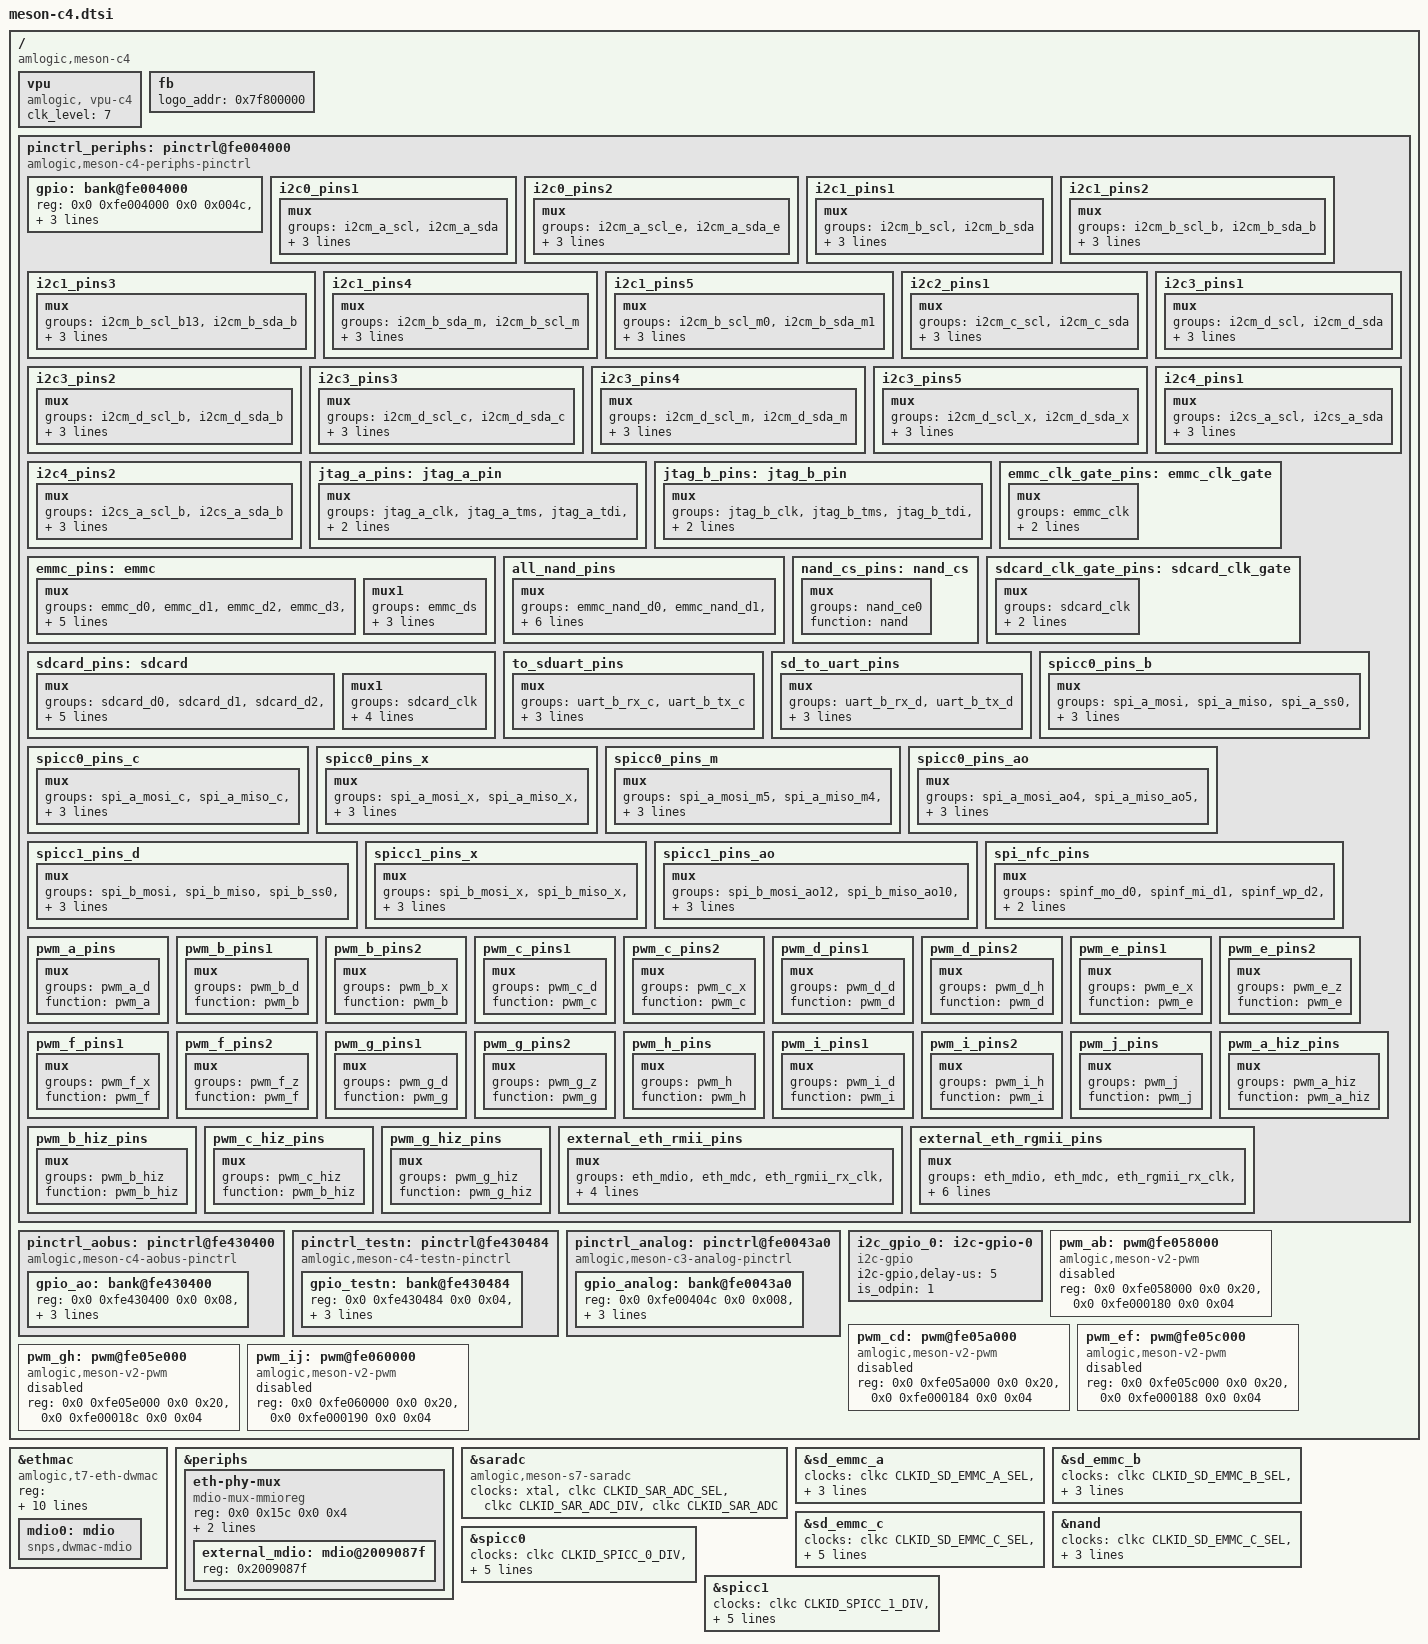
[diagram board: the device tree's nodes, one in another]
// SPDX-License-Identifier: (GPL-2.0+ OR MIT)
/*
 * Copyright (c) 2019 Amlogic, Inc. All rights reserved.
 */

#include "amlogic/meson-c4-series.dtsi"
#include <dt-bindings/amlogic/gpio/meson-c4-gpio.h>
#include <dt-bindings/reset/amlogic,meson-gxbb-reset.h>
#include <dt-bindings/amlogic/pwm/pwm.h>
#include <dt-bindings/amlogic/pwm/meson.h>

/ {
	compatible = "amlogic,meson-c4";

	vpu: vpu {
		compatible = "amlogic, vpu-c4";
		status = "okay";
		/*clocks = <&clkc CLKID_VAPB_MUX>,
		 *	<&clkc CLKID_VPU_INTR>,
		 *	<&clkc CLKID_VPU_P0_COMP>,
		 *	<&clkc CLKID_VPU_P1_COMP>,
		 *	<&clkc CLKID_VPU_MUX>;
		 *clock-names = "vapb_clk",
		 *	"vpu_intr_gate",
		 *	"vpu_clk0",
		 *	"vpu_clk1",
		 *	"vpu_clk";
		 */
		clk_level = <7>;
		/* 0: 100.0M    1: 166.7M    2: 200.0M    3: 250.0M */
		/* 4: 333.3M    5: 400.0M    6: 500.0M    7: 666.7M */
	};

	fb {
		status = "okay";
		logo_addr = "0x7f800000";
	};

	pinctrl_periphs: pinctrl@fe004000 {
		compatible = "amlogic,meson-c4-periphs-pinctrl";
		#address-cells = <2>;
		#size-cells = <2>;
		ranges;

		gpio: bank@fe004000 {
			reg = <0x0 0xfe004000 0x0 0x004c>,
			      <0x0 0xfe0040c0 0x0 0x0240>;
			reg-names = "mux",
				    "gpio";
			gpio-controller;
			#gpio-cells = <2>;
			gpio-ranges = <&pinctrl_periphs 0 0 55>;
		};
	};

	pinctrl_aobus: pinctrl@fe430400 {
		compatible = "amlogic,meson-c4-aobus-pinctrl";
		#address-cells = <2>;
		#size-cells = <2>;
		ranges;

		gpio_ao: bank@fe430400 {
			reg = <0x0 0xfe430400 0x0 0x08>,
			      <0x0 0xfe430408 0x0 0x20>;
			reg-names = "mux", "gpio";
			gpio-controller;
			#gpio-cells = <2>;
			gpio-ranges = <&pinctrl_aobus 0 0 14>;
		};
	};

	pinctrl_testn: pinctrl@fe430484 {
		compatible = "amlogic,meson-c4-testn-pinctrl";
		#address-cells = <2>;
		#size-cells = <2>;
		ranges;

		gpio_testn: bank@fe430484 {
			reg = <0x0 0xfe430484 0x0 0x04>,
			      <0x0 0xfe430464 0x0 0x20>;
			reg-names = "mux", "gpio";
			gpio-controller;
			#gpio-cells = <2>;
			gpio-ranges = <&pinctrl_testn 0 0 1>;
		};
	};


	pinctrl_analog: pinctrl@fe0043a0 {
		compatible = "amlogic,meson-c3-analog-pinctrl";
		#address-cells = <2>;
		#size-cells = <2>;
		ranges;

		gpio_analog: bank@fe0043a0 {
			reg = <0x0 0xfe00404c 0x0 0x008>,
			      <0x0 0xfe00438c 0x0 0x030>;
			reg-names = "mux",
				    "gpio";
			gpio-controller;
			#gpio-cells = <2>;
			gpio-ranges = <&pinctrl_periphs 0 0 14>;
		};
	};

	i2c_gpio_0: i2c-gpio-0 {
		#address-cells = <1>;
		#size-cells = <0>;

		compatible = "i2c-gpio";
		status = "okay";
		//gpios = <&gpio GPIOH_0 GPIO_ACTIVE_HIGH>, /* SDA */
		//	<&gpio GPIOH_1 GPIO_ACTIVE_HIGH>; /* CLK */

		i2c-gpio,delay-us = <5>;
		is_odpin = <1>;
	};

	pwm_ab: pwm@fe058000 {
		compatible = "amlogic,meson-v2-pwm";
		reg = <0x0 0xfe058000  0x0 0x20>,
			<0x0 0xfe000180  0x0 0x04>;
		#pwm-cells = <3>;
		status = "disabled";
	};

	pwm_cd: pwm@fe05a000 {
		compatible = "amlogic,meson-v2-pwm";
		reg = <0x0 0xfe05a000  0x0 0x20>,
			<0x0 0xfe000184  0x0 0x04>;
		#pwm-cells = <3>;
		status = "disabled";
	};

	pwm_ef: pwm@fe05c000 {
		compatible = "amlogic,meson-v2-pwm";
		reg = <0x0 0xfe05c000  0x0 0x20>,
			<0x0 0xfe000188  0x0 0x04>;
		#pwm-cells = <3>;
		status = "disabled";
	};

	pwm_gh: pwm@fe05e000 {
		compatible = "amlogic,meson-v2-pwm";
		reg = <0x0 0xfe05e000  0x0 0x20>,
			<0x0 0xfe00018c  0x0 0x04>;
			#pwm-cells = <3>;
		status = "disabled";
	};

	pwm_ij: pwm@fe060000 {
		compatible = "amlogic,meson-v2-pwm";
		reg = <0x0 0xfe060000  0x0 0x20>,
			<0x0 0xfe000190  0x0 0x04>;
		#pwm-cells = <3>;
		status = "disabled";
	};
};

&ethmac {
	compatible = "amlogic,t7-eth-dwmac";
	reg = <0x0 0xfe308000 0x0 0x12ec
		0x0 0xfe304000 0x0 0x2c
		0x0 0xfe300000 0x0 0x198>;
	reg-names = "eth_base", "eth_top", "eth_cfg";
	phy_cntl1 = <0x41054147>;
	internal_phy = <1>;
	mc_val = <0x4be04>;
	phy-mii-clk-sel = <0x3>;
	ephy_clk_gate = <0x7>;
	pll_val = <0x608200a0 0xea002000 0x00000150>;
	analog_val = <0x20200000 0x0000c000 0x00000023>;
	chip_num = <3>;
	soc_num = <5>;
	/* 5: S1A, S7 */
	//tx_amp_src = <0xfe005b30>;
//	clocks = <&clkc CLKID_ETH_CORE>,
//		 <&clkc CLKID_FCLK_DIV2>,
//		 <&clkc CLKID_MPLL2>;
//	clock-names = "stmmaceth", "clkin0", "clkin1";

	mdio0: mdio {
		#address-cells = <1>;
		#size-cells = <0>;
		compatible = "snps,dwmac-mdio";
	};
};

&periphs {

	eth-phy-mux {
		compatible = "mdio-mux-mmioreg", "mdio-mux";
		#address-cells = <1>;
		#size-cells = <0>;
		reg = <0x0 0x15c 0x0 0x4>;
		mux-mask = <0xffffffff>;
		mdio-parent-bus = <&mdio0>;

		external_mdio: mdio@2009087f {
			reg = <0x2009087f>;
			#address-cells = <1>;
			#size-cells = <0>;
		};
	};
};

&saradc {
	compatible = "amlogic,meson-s7-saradc", "amlogic,meson-saradc";
	clocks = <&xtal>,
		 <&clkc CLKID_SAR_ADC_SEL>,
		 <&clkc CLKID_SAR_ADC_DIV>,
		 <&clkc CLKID_SAR_ADC>;
	clock-names = "xtal", "adc_mux", "adc_div", "adc_gate";
};

&sd_emmc_a {
	clocks = <&clkc CLKID_SD_EMMC_A_SEL>,
		    <&clkc CLKID_SD_EMMC_A_DIV>,
			<&clkc CLKID_SD_EMMC_A>,
			<&clkc CLKID_FCLK_DIV2>,
			<&xtal>;
			clock-names = "mux", "div", "gate", "clkin", "xtal";
};

&sd_emmc_b {
	clocks = <&clkc CLKID_SD_EMMC_B_SEL>,
		    <&clkc CLKID_SD_EMMC_B_DIV>,
			<&clkc CLKID_SD_EMMC_B>,
			<&clkc CLKID_FCLK_DIV2>,
			<&xtal>;
			clock-names = "mux", "div", "gate", "clkin", "xtal";
};

&sd_emmc_c {
	clocks = <&clkc CLKID_SD_EMMC_C_SEL>,
			<&clkc CLKID_SD_EMMC_C_DIV>,
			<&clkc CLKID_SD_EMMC_C>,
			<&clkc CLKID_GP0_PLL>,
			<&xtal>;
			clock-names = "mux", "div", "gate", "clkin", "xtal";
	assigned-clocks = <&clkc CLKID_GP0_PLL>;
	assigned-clock-rates = <1152000000>;
};

&nand {
	clocks = <&clkc CLKID_SD_EMMC_C_SEL>,
			<&clkc CLKID_SD_EMMC_C_DIV>,
			<&clkc CLKID_SD_EMMC_C>,
			<&clkc CLKID_FCLK_DIV2>,
			<&xtal>;
	clock-names = "mux", "div", "gate", "fdiv2", "xtal";
};

&spicc0 {
	clocks = <&clkc CLKID_SPICC_0_DIV>, <&clkc CLKID_SPICC_0>;
	clock-names = "spi_clk", "sys_clk";
	assigned-clocks = <&clkc CLKID_SPICC_0_SEL>, <&clkc CLKID_SPICC_0_DIV>;
	assigned-clock-parents = <&clkc CLKID_FCLK_DIV2>;
	assigned-clock-rates = <0>, <500000000>;
};

&spicc1 {
	clocks = <&clkc CLKID_SPICC_1_DIV>, <&clkc CLKID_SPICC_1>;
	clock-names = "spi_clk", "sys_clk";
	assigned-clocks = <&clkc CLKID_SPICC_1_SEL>, <&clkc CLKID_SPICC_1_DIV>;
	assigned-clock-parents = <&clkc CLKID_FCLK_DIV2>;
	assigned-clock-rates = <0>, <500000000>;
};

&pinctrl_periphs {
	i2c0_pins1:i2c0_pins1 {
		mux {
			groups = "i2cm_a_scl",
				"i2cm_a_sda";
			function = "i2c0";
			drive-strength = <3>;
			bias-disable;
		};
	};

	i2c0_pins2:i2c0_pins2 {
		mux {
			groups = "i2cm_a_scl_e",
				"i2cm_a_sda_e";
			function = "i2c0";
			drive-strength = <3>;
			bias-disable;
		};
	};

	i2c1_pins1:i2c1_pins1 {
		mux {
			groups = "i2cm_b_scl",
				"i2cm_b_sda";
			function = "i2c1";
			drive-strength = <3>;
			bias-disable;
		};
	};

	i2c1_pins2:i2c1_pins2 {
		mux {
			groups = "i2cm_b_scl_b",
				"i2cm_b_sda_b";
			function = "i2c1";
			drive-strength = <3>;
			bias-disable;
		};
	};

	i2c1_pins3:i2c1_pins3 {
		mux {
			groups = "i2cm_b_scl_b13",
				"i2cm_b_sda_b";
			function = "i2c1";
			drive-strength = <3>;
			bias-disable;
		};
	};

	i2c1_pins4:i2c1_pins4 {
		mux {
			groups = "i2cm_b_sda_m",
				"i2cm_b_scl_m";
			function = "i2c1";
			drive-strength = <3>;
			bias-disable;
		};
	};

	i2c1_pins5:i2c1_pins5 {
		mux {
			groups = "i2cm_b_scl_m0",
				"i2cm_b_sda_m1";
			function = "i2c1";
			drive-strength = <3>;
			bias-disable;
		};
	};

	i2c2_pins1:i2c2_pins1 {
		mux {
			groups = "i2cm_c_scl",
				"i2cm_c_sda";
			function = "i2c2";
			drive-strength = <3>;
			bias-disable;
		};
	};

	i2c3_pins1:i2c3_pins1 {
		mux {
			groups = "i2cm_d_scl",
				"i2cm_d_sda";
			function = "i2c3";
			drive-strength = <3>;
			bias-disable;
		};
	};

	i2c3_pins2:i2c3_pins2 {
		mux {
			groups = "i2cm_d_scl_b",
				"i2cm_d_sda_b";
			function = "i2c3";
			drive-strength = <3>;
			bias-disable;
		};
	};

	i2c3_pins3:i2c3_pins3 {
		mux {
			groups = "i2cm_d_scl_c",
				"i2cm_d_sda_c";
			function = "i2c3";
			drive-strength = <3>;
			bias-disable;
		};
	};

	i2c3_pins4:i2c3_pins4 {
		mux {
			groups = "i2cm_d_scl_m",
				"i2cm_d_sda_m";
			function = "i2c3";
			drive-strength = <3>;
			bias-disable;
		};
	};

	i2c3_pins5:i2c3_pins5 {
		mux {
			groups = "i2cm_d_scl_x",
				"i2cm_d_sda_x";
			function = "i2c3";
			drive-strength = <3>;
			bias-disable;
		};
	};

	i2c4_pins1:i2c4_pins1 {
		mux {
			groups = "i2cs_a_scl",
				"i2cs_a_sda";
			function = "i2c4";
			drive-strength = <3>;
			bias-disable;
		};
	};

	i2c4_pins2:i2c4_pins2 {
		mux {
			groups = "i2cs_a_scl_b",
				"i2cs_a_sda_b";
			function = "i2c4";
			drive-strength = <3>;
			bias-disable;
		};
	};

	jtag_a_pins:jtag_a_pin {
		mux {
			groups = "jtag_a_clk",
			"jtag_a_tms",
			"jtag_a_tdi",
			"jtag_a_tdo";
			function = "jtag_a";
		};
	};

	jtag_b_pins:jtag_b_pin {
		mux {
			groups = "jtag_b_clk",
			"jtag_b_tms",
			"jtag_b_tdi",
			"jtag_b_tdo";
			function = "jtag_b";
		};
	};

	emmc_pins: emmc {
		mux {
			groups = "emmc_d0",
				"emmc_d1",
				"emmc_d2",
				"emmc_d3",
				"emmc_d4",
				"emmc_d5",
				"emmc_d6",
				"emmc_d7",
				"emmc_clk",
				"emmc_cmd";
			function = "emmc";
			bias-pull-up;
			input-enable;
		};
		mux1 {
			groups = "emmc_ds";
			function = "emmc";
			input-enable;
			bias-pull-down;
		};
	};

	emmc_clk_gate_pins: emmc_clk_gate {
		mux {
			groups = "emmc_clk";
			function = "emmc";
			bias-pull-down;
		};
	};

	all_nand_pins: all_nand_pins {
		mux {
			groups =  "emmc_nand_d0",
				"emmc_nand_d1",
				"emmc_nand_d2",
				"emmc_nand_d3",
				"emmc_nand_d4",
				"emmc_nand_d5",
				"emmc_nand_d6",
				"emmc_nand_d7",
				"nand_ce0",
				"nand_ale",
				"nand_cle",
				"nand_wen_clk",
				"nand_ren_wr";
			function = "nand";
			input-enable;
		};
	};

	nand_cs_pins: nand_cs {
		mux {
			groups = "nand_ce0";
			function = "nand";
		};
	};

	sdcard_pins: sdcard {
		mux {
			groups = "sdcard_d0",
				"sdcard_d1",
				"sdcard_d2",
				"sdcard_d3",
				"sdcard_cmd";
			function = "sdcard";
			bias-pull-up;
			input-enable;
			drive-strength = <4>;
		};
		mux1 {
			groups ="sdcard_clk";
			function = "sdcard";
			bias-pull-up;
			output-high;
			drive-strength = <4>;
		};
	};

	sdcard_clk_gate_pins: sdcard_clk_gate {
		mux {
			groups = "sdcard_clk";
			function = "sdcard";
			bias-pull-down;
		};
	};

	to_sduart_pins: to_sduart_pins{
		mux {
			groups = "uart_b_rx_c", "uart_b_tx_c";
			function = "uart_b";
			bias-pull-up;
			input-enable;
		};
	};

	sd_to_uart_pins: sd_to_uart_pins{
		mux {
			groups = "uart_b_rx_d", "uart_b_tx_d";
			function = "uart_b";
			bias-pull-up;
			input-enable;
		};
	};

	spicc0_pins_b: spicc0_pins_b {
		mux {
			groups = "spi_a_mosi",
				 "spi_a_miso",
				 "spi_a_ss0",
				 //"spi_a_ss1",
				 //"spi_a_ss2",
				 "spi_a_sclk";
			function = "spi_a";
			drive-strength-microamp = <3000>;
		};
	};

	spicc0_pins_c: spicc0_pins_c {
		mux {
			groups = "spi_a_mosi_c",
				 "spi_a_miso_c",
				 "spi_a_ss0_c",
				 //"spi_a_ss1_c",
				 "spi_a_sclk_c";
			function = "spi_a";
			drive-strength-microamp = <3000>;
		};
	};

	spicc0_pins_x: spicc0_pins_x {
		mux {
			groups = "spi_a_mosi_x",
				 "spi_a_miso_x",
				 "spi_a_ss0_x",
				 //"spi_a_ss1_x",
				 //"spi_a_ss2_x",
				 "spi_a_sclk_x";
			function = "spi_a";
			drive-strength-microamp = <3000>;
		};
	};

	spicc0_pins_m: spicc0_pins_m {
		mux {
			groups = "spi_a_mosi_m5",
				 "spi_a_miso_m4",
				 //"spi_a_mosi_m",
				 //"spi_a_miso_m",
				 "spi_a_ss0_m",
				 "spi_a_sclk_m";
			function = "spi_a";
			drive-strength-microamp = <3000>;
		};
	};

	spicc0_pins_ao: spicc0_pins_ao {
		mux {
			groups = "spi_a_mosi_ao4",
				 "spi_a_miso_ao5",
				 "spi_a_ss0_ao7",
				 "spi_a_sclk_ao6";
			function = "spi_a";
			drive-strength-microamp = <3000>;
		};
	};

	spicc1_pins_d: spicc1_pins_d {
		mux {
			groups = "spi_b_mosi",
				 "spi_b_miso",
				 "spi_b_ss0",
				 "spi_b_ss1",
				 "spi_b_sclk";
			function = "spi_b";
			drive-strength-microamp = <3000>;
		};
	};

	spicc1_pins_x: spicc1_pins_x {
		mux {
			groups = "spi_b_mosi_x",
				 "spi_b_miso_x",
				 "spi_b_ss1_x",
				 "spi_b_sclk_x";
			function = "spi_b";
			drive-strength-microamp = <3000>;
		};
	};

	spicc1_pins_ao: spicc1_pins_ao {
		mux {
			groups = "spi_b_mosi_ao12",
				 "spi_b_miso_ao10",
				 "spi_b_ss0_ao13",
				 "spi_b_sclk_ao11";
			function = "spi_b";
			drive-strength-microamp = <3000>;
		};
	};

	spi_nfc_pins: spi_nfc_pins {
		mux {
			groups = "spinf_mo_d0",
				 "spinf_mi_d1",
				 "spinf_wp_d2",
				 "spinf_hold_d3",
				 "spinf_clk",
				 "spinf_cs0";
			function = "spinf";
		};
	};

	pwm_a_pins: pwm_a_pins {
		mux {
			groups = "pwm_a_d";
			function = "pwm_a";
		};
	};

	pwm_b_pins1: pwm_b_pins1 {
		mux {
			groups = "pwm_b_d";
			function = "pwm_b";
		};
	};

	pwm_b_pins2: pwm_b_pins2 {
		mux {
			groups = "pwm_b_x";
			function = "pwm_b";
		};
	};

	pwm_c_pins1: pwm_c_pins1 {
		mux {
			groups = "pwm_c_d";
			function = "pwm_c";
		};
	};

	pwm_c_pins2: pwm_c_pins2 {
		mux {
			groups = "pwm_c_x";
			function = "pwm_c";
		};
	};

	pwm_d_pins1: pwm_d_pins1 {
		mux {
			groups = "pwm_d_d";
			function = "pwm_d";
		};
	};

	pwm_d_pins2: pwm_d_pins2 {
		mux {
			groups = "pwm_d_h";
			function = "pwm_d";
		};
	};

	pwm_e_pins1: pwm_e_pins1 {
		mux {
			groups = "pwm_e_x";
			function = "pwm_e";
		};
	};

	pwm_e_pins2: pwm_e_pins2 {
		mux {
			groups = "pwm_e_z";
			function = "pwm_e";
		};
	};

	pwm_f_pins1: pwm_f_pins1 {
		mux {
			groups = "pwm_f_x";
			function = "pwm_f";
		};
	};

	pwm_f_pins2: pwm_f_pins2 {
		mux {
			groups = "pwm_f_z";
			function = "pwm_f";
		};
	};

	pwm_g_pins1: pwm_g_pins1 {
		mux {
			groups = "pwm_g_d";
			function = "pwm_g";
		};
	};

	pwm_g_pins2: pwm_g_pins2 {
		mux {
			groups = "pwm_g_z";
			function = "pwm_g";
		};
	};

	pwm_h_pins: pwm_h_pins {
		mux {
			groups = "pwm_h";
			function = "pwm_h";
		};
	};

	pwm_i_pins1: pwm_i_pins1 {
		mux {
			groups = "pwm_i_d";
			function = "pwm_i";
		};
	};

	pwm_i_pins2: pwm_i_pins2 {
		mux {
			groups = "pwm_i_h";
			function = "pwm_i";
		};
	};

	pwm_j_pins: pwm_j_pins {
		mux {
			groups = "pwm_j";
			function = "pwm_j";
		};
	};

	pwm_a_hiz_pins: pwm_a_hiz_pins {
		mux {
			groups = "pwm_a_hiz";
			function = "pwm_a_hiz";
		};
	};

	pwm_b_hiz_pins: pwm_b_hiz_pins {
		mux {
			groups = "pwm_b_hiz";
			function = "pwm_b_hiz";
		};
	};

	pwm_c_hiz_pins: pwm_c_hiz_pins {
		mux {
			groups = "pwm_c_hiz";
			function = "pwm_b_hiz";
		};
	};

	pwm_g_hiz_pins: pwm_g_hiz_pins {
		mux {
			groups = "pwm_g_hiz";
			function = "pwm_g_hiz";
		};
	};

	external_eth_rmii_pins: external_eth_rmii_pins {
		mux {
			groups = "eth_mdio",
				"eth_mdc",
				"eth_rgmii_rx_clk",
				"eth_rx_dv",
				"eth_rxd0",
				"eth_rxd1",
				"eth_txen",
				"eth_txd0",
				"eth_txd1";
			function = "eth";
			drive-strength = <3>;
		};
	};

	external_eth_rgmii_pins: external_eth_rgmii_pins {
		mux {
			groups = "eth_mdio",
				"eth_mdc",
				"eth_rgmii_rx_clk",
				"eth_rx_dv",
				"eth_rxd0",
				"eth_rxd1",
				"eth_rxd2_rgmii",
				"eth_rxd3_rgmii",
				"eth_rgmii_tx_clk",
				"eth_txen",
				"eth_txd0",
				"eth_txd1",
				"eth_txd2_rgmii",
				"eth_txd3_rgmii";
			function = "eth";
			drive-strength = <3>;
		};
	};
};
